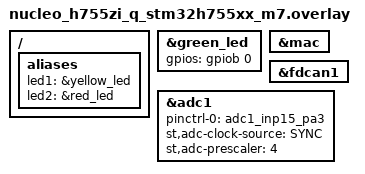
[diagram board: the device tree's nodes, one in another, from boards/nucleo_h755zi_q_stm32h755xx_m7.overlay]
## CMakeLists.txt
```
cmake_minimum_required(VERSION 3.20.0)

set(OPENBSW_DIR
    ${CMAKE_CURRENT_SOURCE_DIR}/../../openbsw
    CACHE PATH "Path to Eclipse OpenBSW")

set(OPENBSW_CONFIG_DIR ${CMAKE_CURRENT_SOURCE_DIR}/../openbswConfig)

set(INCLUDE_OPENBSW_LIBS_BSP
    OFF
    CACHE BOOL "Include openbsw/libs/bsp/ in build")

add_compile_options($<TARGET_PROPERTY:zephyr_interface,INTERFACE_COMPILE_OPTIONS>)

find_package(Zephyr REQUIRED HINTS $ENV{ZEPHYR_BASE})

project(body_ecu LANGUAGES C CXX)

set(LIBS_ROOT ${CMAKE_CURRENT_SOURCE_DIR}/../libs)

include(${OPENBSW_DIR}/Filelists.cmake)

# OpenBSW forces CXX_STANDARD=14; body-ecu requires C++17
set(CMAKE_CXX_STANDARD 17)
set(CMAKE_CXX_STANDARD_REQUIRED ON)

# openbsw-zephyr adaptation libraries (only asyncZephyr + bspZephyr, not zephyrEthAdapter)
set(OPENBSW_ZEPHYR_DIR ${CMAKE_CURRENT_SOURCE_DIR}/../../modules/openbsw-zephyr/libs)
add_subdirectory(${OPENBSW_ZEPHYR_DIR}/asyncZephyr ${CMAKE_CURRENT_BINARY_DIR}/asyncZephyr)
add_subdirectory(${OPENBSW_ZEPHYR_DIR}/bspZephyr ${CMAKE_CURRENT_BINARY_DIR}/bspZephyr)

add_library(asyncPlatform ALIAS asyncZephyr)

# OpenBSW configuration (use Zephyr async binding)
add_subdirectory(${OPENBSW_CONFIG_DIR}/asyncCoreConfiguration
    ${CMAKE_CURRENT_BINARY_DIR}/asyncCoreConfiguration)
add_subdirectory(${OPENBSW_CONFIG_DIR}/asyncBindingZephyr
    ${CMAKE_CURRENT_BINARY_DIR}/asyncBinding)
add_subdirectory(${OPENBSW_CONFIG_DIR}/configuration
    ${CMAKE_CURRENT_BINARY_DIR}/configuration)

# SOME/IP code generation from services.yaml
include(${CMAKE_CURRENT_SOURCE_DIR}/../cmake/someip_codegen.cmake)

# Port interfaces (header-only)
add_subdirectory(${LIBS_ROOT}/platform/ports ${CMAKE_CURRENT_BINARY_DIR}/ports)

# Domain modules
add_subdirectory(${LIBS_ROOT}/body/lighting ${CMAKE_CURRENT_BINARY_DIR}/lighting)
add_subdirectory(${LIBS_ROOT}/body/door-lock ${CMAKE_CURRENT_BINARY_DIR}/door-lock)
add_subdirectory(${LIBS_ROOT}/body/vehicle-mode ${CMAKE_CURRENT_BINARY_DIR}/vehicle-mode)
add_subdirectory(${LIBS_ROOT}/body/speed-simulator ${CMAKE_CURRENT_BINARY_DIR}/speed-simulator)
add_subdirectory(${LIBS_ROOT}/body/ignition ${CMAKE_CURRENT_BINARY_DIR}/ignition)

# Platform modules
add_subdirectory(${LIBS_ROOT}/platform/can-gateway ${CMAKE_CURRENT_BINARY_DIR}/can-gateway)
add_subdirectory(${LIBS_ROOT}/platform/diagnostics ${CMAKE_CURRENT_BINARY_DIR}/diagnostics)

# Platform adapters
add_subdirectory(${LIBS_ROOT}/adapters/zephyr ${CMAKE_CURRENT_BINARY_DIR}/adapters-zephyr)
add_subdirectory(${LIBS_ROOT}/adapters/system ${CMAKE_CURRENT_BINARY_DIR}/adapters-system)

target_sources(app PRIVATE src/main.cpp)
target_include_directories(app PRIVATE
    ${LIBS_ROOT}/adapters/system/include
    ${LIBS_ROOT}/adapters/zephyr/include
)
target_link_libraries(app PRIVATE
    ports
    lifecycle
    lighting
    door_lock
    vehicle_mode
    speed_simulator
    ignition
    can_gateway
    diagnostics
    adapters_zephyr
    adapters_system
    someip_ids
    asyncBinding
    asyncZephyrImpl
    configuration
    bspZephyr
    logger
    loggerIntegration
    etl
)

# Stage firmware + Renode scripts in one place for CI/packaging.
set(BODY_ECU_ARTIFACTS_DIR ${CMAKE_BINARY_DIR}/artifacts)

set(BODY_ECU_FIRMWARE_ARTIFACTS ${CMAKE_BINARY_DIR}/zephyr/zephyr.elf)
if(CONFIG_BUILD_OUTPUT_HEX)
    list(APPEND BODY_ECU_FIRMWARE_ARTIFACTS ${CMAKE_BINARY_DIR}/zephyr/zephyr.hex)
endif()
if(CONFIG_BUILD_OUTPUT_BIN)
    list(APPEND BODY_ECU_FIRMWARE_ARTIFACTS ${CMAKE_BINARY_DIR}/zephyr/zephyr.bin)
endif()

set(BODY_ECU_RENODE_RESC_FILES
    ${CMAKE_CURRENT_SOURCE_DIR}/../renode/body_ecu.resc
    ${CMAKE_CURRENT_SOURCE_DIR}/../renode/body_ecu_vnet.resc
    ${CMAKE_CURRENT_SOURCE_DIR}/../renode/body_ecu_renode_tap.resc
)

add_custom_target(body_ecu_artifacts
    COMMAND ${CMAKE_COMMAND} -E make_directory ${BODY_ECU_ARTIFACTS_DIR}/firmware
    COMMAND ${CMAKE_COMMAND} -E make_directory ${BODY_ECU_ARTIFACTS_DIR}/renode
    COMMAND ${CMAKE_COMMAND} -E copy_if_different
        ${BODY_ECU_FIRMWARE_ARTIFACTS}
        ${BODY_ECU_ARTIFACTS_DIR}/firmware
    COMMAND ${CMAKE_COMMAND} -E copy_if_different
        ${BODY_ECU_RENODE_RESC_FILES}
        ${BODY_ECU_ARTIFACTS_DIR}/renode
    COMMENT "Copying body-ecu firmware and Renode scripts to artifacts/"
    VERBATIM
)
```

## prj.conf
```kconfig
CONFIG_CPP=y
CONFIG_STD_CPP17=y
CONFIG_REQUIRES_FULL_LIBCPP=y
CONFIG_LOG=y
CONFIG_LOG_DEFAULT_LEVEL=3
CONFIG_LOG_PRINTK=n
CONFIG_LOG_BUFFER_SIZE=4096
CONFIG_MAIN_STACK_SIZE=8192
CONFIG_SYSTEM_WORKQUEUE_STACK_SIZE=4096
CONFIG_HEAP_MEM_POOL_SIZE=16384
CONFIG_EVENTS=y
CONFIG_THREAD_STACK_INFO=y
```

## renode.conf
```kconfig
# Overrides for Renode emulation.
# STM32H7 ADC calibration hangs in Renode -- the built-in STM32F0_ADC model
# doesn't implement the H7's DEEPPWD/ADVREGEN/ADCAL register sequence, so
# the Zephyr ADC driver spins forever during device init.
# Replacing the Renode ADC model requires PythonPeripheral peripheral
# overrides which are not reliably supported across Renode versions.
CONFIG_ADC=n
```

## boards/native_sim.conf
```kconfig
CONFIG_DEBUG=y
CONFIG_POSIX_API=y
CONFIG_GLIBCXX_LIBCPP=y
```

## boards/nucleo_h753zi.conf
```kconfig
CONFIG_CAN=n

CONFIG_NETWORKING=y
CONFIG_NET_L2_ETHERNET=y
CONFIG_NET_IPV4=y
CONFIG_NET_UDP=y
CONFIG_NET_SOCKETS=y
CONFIG_NET_CONFIG_SETTINGS=y
CONFIG_NET_CONFIG_MY_IPV4_ADDR="192.168.100.10"
CONFIG_NET_CONFIG_PEER_IPV4_ADDR="192.168.100.1"
CONFIG_NET_CONFIG_MY_IPV4_NETMASK="255.255.255.0"

CONFIG_POSIX_API=y
CONFIG_GLIBCXX_LIBCPP=y
CONFIG_HEAP_MEM_POOL_SIZE=131072
CONFIG_ADC=y
CONFIG_SOMEIP=y
CONFIG_SOMEIP_TRANSPORT_UDP=y
CONFIG_SOMEIP_THREAD_STACK_SIZE=8192

CONFIG_NET_PKT_RX_COUNT=16
CONFIG_NET_PKT_TX_COUNT=16
CONFIG_NET_BUF_RX_COUNT=32
CONFIG_NET_BUF_TX_COUNT=32
```

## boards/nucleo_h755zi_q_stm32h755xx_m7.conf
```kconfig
CONFIG_DEBUG=y
CONFIG_PM=n

CONFIG_NETWORKING=y
CONFIG_NET_L2_ETHERNET=y
CONFIG_NET_IPV4=y
CONFIG_NET_UDP=y
CONFIG_NET_TCP=y
CONFIG_NET_SOCKETS=y
CONFIG_NET_CONFIG_SETTINGS=y
CONFIG_NET_CONFIG_MY_IPV4_ADDR="192.168.100.10"
CONFIG_NET_CONFIG_PEER_IPV4_ADDR="192.168.100.1"
CONFIG_NET_CONFIG_MY_IPV4_NETMASK="255.255.255.0"
CONFIG_GPIO=y
CONFIG_CAN=y
CONFIG_CAN_FD_MODE=y
CONFIG_GLIBCXX_LIBCPP=y

CONFIG_POSIX_API=y
CONFIG_HEAP_MEM_POOL_SIZE=131072
CONFIG_ADC=y
CONFIG_SOMEIP=y
CONFIG_SOMEIP_TRANSPORT_UDP=y
CONFIG_SOMEIP_THREAD_STACK_SIZE=8192

CONFIG_NET_PKT_RX_COUNT=16
CONFIG_NET_PKT_TX_COUNT=16
CONFIG_NET_BUF_RX_COUNT=32
CONFIG_NET_BUF_TX_COUNT=32
```

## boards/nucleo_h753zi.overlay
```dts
/* Add the red user LED (LD3, PB14) as a GPIO-controlled LED.
 * The in-tree DTS only exposes it as pwm-led0; the app needs led2. */

/ {
	leds {
		compatible = "gpio-leds";

		red_led: led_2 {
			gpios = <&gpiob 14 GPIO_ACTIVE_HIGH>;
			label = "User LD3";
		};
	};

	aliases {
		led2 = &red_led;
	};
};
```

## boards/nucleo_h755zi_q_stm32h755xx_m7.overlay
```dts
/* Devicetree overlay for NUCLEO-H755ZI-Q (M7 core) */
/* Enables Ethernet, CAN, user LEDs, and user button */

&green_led {
	gpios = <&gpiob 0 GPIO_ACTIVE_HIGH>;
};

/ {
	aliases {
		led1 = &yellow_led;
		led2 = &red_led;
	};
};

&mac {
	status = "okay";
};

&fdcan1 {
	status = "okay";
};

&adc1 {
	pinctrl-0 = <&adc1_inp15_pa3>;
	pinctrl-names = "default";
	st,adc-clock-source = "SYNC";
	st,adc-prescaler = <4>;
	status = "okay";
};
```

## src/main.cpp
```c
#include <zephyr/kernel.h>
#include <zephyr/logging/log.h>
#include <optional>

LOG_MODULE_REGISTER(body_ecu, LOG_LEVEL_INF);

#ifdef CONFIG_GPIO
#include <zephyr/drivers/gpio.h>
#endif

#ifdef CONFIG_CAN
#include <zephyr/drivers/can.h>
#endif

#ifdef CONFIG_ADC
#include <zephyr/drivers/adc.h>
#endif

#include <async/AsyncBinding.h>
#include <lifecycle/LifecycleManager.h>
#include <bsp/timer/SystemTimer.h>
#include <util/estd/assert.h>

#include "CanGatewaySystem.h"
#include "DiagnosticsSystem.h"
#include "DoCanTransport.h"
#include "DoIpTransport.h"
#include "DoorLockSystem.h"
#include "VehicleInfoProvider.h"
#include "LightingSystem.h"
#include "SomeIpSystem.h"
#include "IgnitionSystem.h"
#include "SpeedSimulatorSystem.h"
#include "VehicleModeSystem.h"

#include "someip_service_ids.h"
#include "ports/NullButtonInput.h"

#ifdef CONFIG_GPIO
#include "zephyr_adapters/ButtonAdapter.h"
#include "zephyr_adapters/CanAdapter.h"
#include "zephyr_adapters/GpioAdapter.h"
#endif

#ifdef CONFIG_ADC
#include "zephyr_adapters/AdcAdapter.h"
#endif

#include "zephyr_adapters/LocalSignalBus.h"
#include "zephyr_adapters/ZephyrTimerService.h"

namespace {

/// STM32H753 DBGMCU IDCODE register.  Real silicon reports DEV_ID = 0x450;
/// Renode typically does not model this peripheral and returns 0.
bool is_real_hardware()
{
    volatile uint32_t idcode = *reinterpret_cast<volatile uint32_t*>(0x5C001000);
    return (idcode & 0xFFF) == 0x450;
}

}  // namespace

using namespace body_ecu;

using AsyncAdapter        = ::async::AsyncBinding::AdapterType;
using AsyncRuntimeMonitor = ::async::AsyncBinding::RuntimeMonitorType;
using AsyncContextHook    = ::async::AsyncBinding::ContextHookType;

static constexpr size_t MaxNumComponents         = 16;
static constexpr size_t MaxNumLevels             = 8;
static constexpr size_t MaxNumComponentsPerLevel = MaxNumComponents;

using LifecycleManager = ::lifecycle::declare::
    LifecycleManager<MaxNumComponents, MaxNumLevels, MaxNumComponentsPerLevel>;

static char const* const isrGroupNames[ISR_GROUP_COUNT] = {"test"};

static AsyncRuntimeMonitor runtimeMonitor{
    AsyncContextHook::InstanceType::GetNameType::create<&AsyncAdapter::getTaskName>(),
    isrGroupNames};

static LifecycleManager lifecycleManager{
    TASK_SYSADMIN,
    ::lifecycle::LifecycleManager::GetTimestampType::create<&getSystemTimeUs32Bit>()};

K_THREAD_STACK_DEFINE(sysadminStack, 2 * 1024);
using SysadminTask = AsyncAdapter::Task<TASK_SYSADMIN, K_THREAD_STACK_SIZEOF(sysadminStack)>;
SysadminTask sysadminTask{"sysadmin", sysadminStack};

K_THREAD_STACK_DEFINE(bodyStack, 4 * 1024);
using BodyTask = AsyncAdapter::Task<TASK_BODY, K_THREAD_STACK_SIZEOF(bodyStack)>;
BodyTask bodyTask{"body", bodyStack};

K_THREAD_STACK_DEFINE(someipStack, 8 * 1024);
using SomeIpTask = AsyncAdapter::Task<TASK_SOMEIP, K_THREAD_STACK_SIZEOF(someipStack)>;
SomeIpTask someipTask{"someip", someipStack};

K_THREAD_STACK_DEFINE(diagStack, 4 * 1024);
using DiagTask = AsyncAdapter::Task<TASK_DIAG, K_THREAD_STACK_SIZEOF(diagStack)>;
DiagTask diagTask{"diag", diagStack};

K_THREAD_STACK_DEFINE(backgroundStack, 2 * 1024);
using BackgroundTask = AsyncAdapter::Task<TASK_BACKGROUND, K_THREAD_STACK_SIZEOF(backgroundStack)>;
BackgroundTask backgroundTask{"background", backgroundStack};

AsyncContextHook contextHook{runtimeMonitor};

int main(void)
{
    ::estd::set_assert_handler(
        [](char const* file, int line, char const* expr) {
            printk("\n*** ASSERT FAILED: file=%s line=%d expr=%s\n",
                   file ? file : "(null)", line, expr ? expr : "(null)");
            k_panic();
        });

    LOG_INF("Body ECU starting (Zephyr + OpenBSW)");
    LOG_INF("Platform: %s", CONFIG_BOARD);

    AsyncAdapter::init();

    bool real_hw = is_real_hardware();
    LOG_INF("Hardware detection: %s (DBGMCU IDCODE=0x%08x)",
            real_hw ? "real silicon" : "emulated (Renode)",
            *reinterpret_cast<volatile uint32_t*>(0x5C001000));

    adapters::SomeIpConfig someip_cfg{
        .host = "0.0.0.0", .port = 30490, .enable_sd = real_hw};
    static adapters::SomeIpSystem someip_system(someip_cfg);

#ifdef CONFIG_GPIO
    static const struct gpio_dt_spec leds[] = {
        GPIO_DT_SPEC_GET_OR(DT_ALIAS(led0), gpios, {0}),
        GPIO_DT_SPEC_GET_OR(DT_ALIAS(led1), gpios, {0}),
        GPIO_DT_SPEC_GET_OR(DT_ALIAS(led2), gpios, {0}),
    };

    std::vector<struct gpio_dt_spec> led_specs(std::begin(leds), std::end(leds));
    static adapters::GpioAdapter gpio_adapter(led_specs);
    bool gpio_ok = gpio_adapter.configure();

    static const struct gpio_dt_spec user_btn =
        GPIO_DT_SPEC_GET_OR(DT_ALIAS(sw0), gpios, {0});
    static adapters::ButtonAdapter button_adapter(user_btn);
    if (gpio_ok) {
        button_adapter.configure();
    }
    if (gpio_ok) {
        for (int blink = 0; blink < 3; ++blink) {
            for (size_t i = 0; i < ARRAY_SIZE(leds); ++i) {
                int rc = gpio_pin_set_dt(&leds[i], 1);
                printk("[blink] led%zu ON rc=%d (port=%p pin=%d)\n",
                       i, rc, (void*)leds[i].port, leds[i].pin);
            }
            k_msleep(200);
            for (size_t i = 0; i < ARRAY_SIZE(leds); ++i) {
                gpio_pin_set_dt(&leds[i], 0);
            }
            k_msleep(200);
        }
        LOG_INF("LED blink test done (3 LEDs x 3 blinks)");
    } else {
        LOG_WRN("GPIO not available -- using software-only door-lock (emulation)");
    }
#endif

    LOG_INF("CP1: after GPIO");

#ifdef CONFIG_CAN
    const struct device* can_dev = DEVICE_DT_GET(DT_CHOSEN(zephyr_canbus));
    static adapters::CanAdapter can_adapter(can_dev);
    can_adapter.configure();
#endif

    LOG_INF("CP2: creating LocalSignalBus");
    static adapters::LocalSignalBus signal_bus;
    LOG_INF("CP3: LocalSignalBus done");

#ifdef CONFIG_GPIO
    static ports::NullButtonInput null_button;
    std::optional<adapters::LightingSystem> lighting;
    std::optional<adapters::DoorLockSystem> door_lock;
    if (gpio_ok) {
        lighting.emplace(gpio_adapter, someip_system);
        body::DoorLockConfig door_cfg;
        door_cfg.lock_gpio_pin = 2;
        door_lock.emplace(gpio_adapter, null_button, someip_system,
                          door_cfg, &signal_bus);
    }
#endif
    // --- Speed Simulator (ADC potentiometer) ---
    static adapters::ZephyrTimerService timer_service;
#ifdef CONFIG_ADC
    const struct device* adc_dev = DEVICE_DT_GET(DT_NODELABEL(adc1));
    static adapters::AdcAdapter adc_adapter(adc_dev);
    bool adc_ok = adc_adapter.configure(15, 12);
    std::optional<adapters::SpeedSimulatorSystem> speed_sim;
    if (real_hw && adc_ok) {
        body::SpeedSimulatorConfig speed_cfg;
        speed_cfg.adc_channel = 15;
        speed_sim.emplace(adc_adapter, someip_system, timer_service,
                          speed_cfg, &signal_bus);
    }
#endif

    LOG_INF("CP4: creating VehicleModeSystem");
    static adapters::VehicleModeSystem vehicle_mode(someip_system);
    LOG_INF("CP5: VehicleModeSystem done");

#ifdef CONFIG_GPIO
    std::optional<adapters::IgnitionSystem> ignition;
    if (gpio_ok) {
        ignition.emplace(button_adapter, vehicle_mode, timer_service,
                         body::IgnitionConfig{}, &signal_bus);
    }
#endif

#ifdef CONFIG_CAN
    static adapters::CanGatewaySystem can_gateway(can_adapter, someip_system);

    platform::ServiceMapping door_gw;
    door_gw.name = "door_status";
    door_gw.direction = platform::GatewayDirection::CanToSomeIp;
    door_gw.someip_service_id = 0x1001;
    door_gw.someip_event_id = 0x8001;
    door_gw.someip_eventgroup_id = 0x0001;
    door_gw.can_id = 0x300;
    door_gw.can_dlc = 2;
    can_gateway.addMapping(door_gw);
#endif

    LOG_INF("CP6: creating VehicleInfoProvider");
    static adapters::VehicleInfoProvider vehicle_info;
    vehicle_info.setVin("WVW00000BODYECU01");
    vehicle_info.setEcuSerial("BECU-ZEP-001");

    someip_system.registerMethod(
        body_ecu::someip::vehicle_info::kServiceId,
        body_ecu::someip::vehicle_info::method::kGetVin,
        [&vehicle_info](const ports::SomeIpMessage& req) {
            ports::SomeIpMessage resp = req;
            resp.message_type = 0x80;
            resp.return_code = 0x00;
            auto vin_data = vehicle_info.readData(adapters::VehicleInfoProvider::kDidVin);
            if (vin_data) {
                resp.payload = vin_data->data;
            }
            return resp;
        });
    someip_system.registerEvent(
        body_ecu::someip::vehicle_info::kServiceId,
        body_ecu::someip::vehicle_info::event::kVinAvailable,
        body_ecu::someip::vehicle_info::eventgroup::kVehicleInfoEvents);
    LOG_INF("Registered vehicle_info SOME/IP service (VIN + event)");

    LOG_INF("CP7: creating DiagnosticsSystem");
    static adapters::DiagnosticsSystem diagnostics;
    LOG_INF("CP8: creating DoIpTransport");
    static adapters::DoIpTransport doip_transport;
#ifdef CONFIG_CAN
    static adapters::DoCanTransport docan_transport(can_adapter);
    diagnostics.addTransport(&docan_transport);
#endif
    diagnostics.addTransport(&doip_transport);
    diagnostics.addProvider(&vehicle_info);
    LOG_INF("CP9: diagnostics wired");

#ifdef CONFIG_GPIO
    if (lighting && door_lock) {
        diagnostics.addProvider(&lighting->controller());
        diagnostics.addProvider(&door_lock->controller());
        vehicle_mode.manager().addObserver(&lighting->controller());
        vehicle_mode.manager().addObserver(&door_lock->controller());
    }
#endif
#ifdef CONFIG_ADC
    if (speed_sim) {
        vehicle_mode.manager().addObserver(&speed_sim->simulator());
    }
#endif

    LOG_INF("CP10: adding lifecycle components");
    lifecycleManager.addComponent("someip", someip_system, 1);
#ifdef CONFIG_GPIO
    if (lighting) lifecycleManager.addComponent("lighting", *lighting, 2);
    if (door_lock) lifecycleManager.addComponent("door_lock", *door_lock, 2);
#endif
    lifecycleManager.addComponent("vehicle_mode", vehicle_mode, 2);
#ifdef CONFIG_GPIO
    if (ignition) lifecycleManager.addComponent("ignition", *ignition, 2);
#endif
#ifdef CONFIG_ADC
    if (speed_sim) lifecycleManager.addComponent("speed_sim", *speed_sim, 2);
#endif
#ifdef CONFIG_CAN
    lifecycleManager.addComponent("can_gateway", can_gateway, 3);
    lifecycleManager.addComponent("docan", docan_transport, 3);
#endif
    lifecycleManager.addComponent("diagnostics", diagnostics, 3);
    lifecycleManager.addComponent("doip", doip_transport, 3);

    LOG_INF("CP11: lifecycle components added");
#ifdef CONFIG_GPIO
    if (!gpio_ok) {
        static body::LockState sw_state = body::LockState::Unlocked;
        body::DoorLockConfig cfg;
        someip_system.registerMethod(cfg.service_id, cfg.lock_method,
            [&](const ports::SomeIpMessage& req) {
                auto old = sw_state;
                sw_state = body::LockState::Locked;
                someip_system.sendEvent(cfg.service_id,
                    cfg.lock_state_changed_event,
                    {static_cast<uint8_t>(old), static_cast<uint8_t>(sw_state)});
                ports::SomeIpMessage resp = req;
                resp.message_type = 0x80;
                resp.return_code = 0x00;
                return resp;
            });
        someip_system.registerMethod(cfg.service_id, cfg.unlock_method,
            [&](const ports::SomeIpMessage& req) {
                auto old = sw_state;
                sw_state = body::LockState::Unlocked;
                someip_system.sendEvent(cfg.service_id,
                    cfg.lock_state_changed_event,
                    {static_cast<uint8_t>(old), static_cast<uint8_t>(sw_state)});
                ports::SomeIpMessage resp = req;
                resp.message_type = 0x80;
                resp.return_code = 0x00;
                return resp;
            });
        someip_system.registerMethod(cfg.service_id, cfg.get_status_method,
            [](const ports::SomeIpMessage& req) {
                ports::SomeIpMessage resp = req;
                resp.message_type = 0x80;
                resp.return_code = 0x00;
                resp.payload = {static_cast<uint8_t>(sw_state)};
                return resp;
            });
        someip_system.registerEvent(cfg.service_id,
            cfg.lock_state_changed_event, cfg.eventgroup_id);
        LOG_INF("Registered software-only door-lock SOME/IP handlers");
    }
#endif

#ifdef CONFIG_ADC
    if (!speed_sim) {
        body::SpeedSimulatorConfig scfg;
        someip_system.registerMethod(scfg.service_id, scfg.get_speed_method,
            [](const ports::SomeIpMessage& req) {
                ports::SomeIpMessage resp = req;
                resp.message_type = 0x80;
                resp.return_code = 0x00;
                resp.payload = {0, 0, 0, 0};
                return resp;
            });
        someip_system.registerMethod(scfg.service_id, scfg.set_speed_method,
            [](const ports::SomeIpMessage& req) {
                ports::SomeIpMessage resp = req;
                resp.message_type = 0x80;
                resp.return_code = 0x00;
                return resp;
            });
        someip_system.registerEvent(scfg.service_id,
            scfg.speed_changed_event, scfg.eventgroup_id);
        LOG_INF("Registered software-only speed SOME/IP handlers (emulation)");
    }
#endif

    LOG_INF("Transitioning to run level 3...");
    lifecycleManager.transitionToLevel(MaxNumLevels);
#ifdef CONFIG_CAN
    can_adapter.startReceiving();
#endif
    LOG_INF("Body ECU ready - all systems running");

    {
        auto vin_data = vehicle_info.readData(adapters::VehicleInfoProvider::kDidVin);
        if (vin_data) {
            someip_system.sendEvent(
                body_ecu::someip::vehicle_info::kServiceId,
                body_ecu::someip::vehicle_info::event::kVinAvailable,
                vin_data->data);
            LOG_INF("Published VIN event via SOME/IP");
        }
    }

    runtimeMonitor.start();
    AsyncAdapter::run();

    k_sleep(K_FOREVER);
    return 0;
}
```
